# NPCX490M register map
File version: 1.0
Registers are 8-bit, read-write, reset 0x0 unless marked. A register's access mark holds for its fields unless they carry their own. Offsets are from the block's base; [hi:lo] are bit positions; {n}, {i} and the like mark numbered series; 'fields as' and 'values as' point back to an identical list.

## FIU_0
Base 0x40020000
Same registers: FIU_1 0x40021000
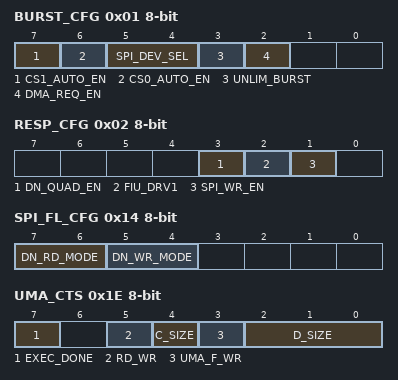
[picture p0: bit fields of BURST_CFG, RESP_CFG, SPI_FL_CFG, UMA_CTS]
0x01 BURST_CFG — Burst Configuration Register (BURST_CFG)
  [7] CS1_AUTO_EN — F_CS1 Auto-Assertion Enable
  [6] CS0_AUTO_EN — F_CS0 Auto-Assertion Enable
  [5:4] SPI_DEV_SEL — SPI Device Select
  [3] UNLIM_BURST — Unlimited Burst
  [2] DMA_REQ_EN — DMA Request Enable
0x02 RESP_CFG — FIU Response Configuration Register (RESP_CFG)
  [3] DN_QUAD_EN — Device 'n' Quad Enable
  [2] FIU_DRV1 — FIU IO2, IO3 Drive High
  [1] SPI_WR_EN — SPI Write Enable
0x14 SPI_FL_CFG — SPI Flash Configuration Register (SPI_FL_CFG)
  [7:6] DN_RD_MODE — Device 'n' Read Mode Select
  [5:4] DN_WR_MODE — Device 'n' Write Mode Select
0x16 UMA_CODE — UMA Code Byte Register (UMA_CODE)
{0x3+i} UMA_AB0-{i} (i=20..22) — UMA Address Byte 0-2 Register (UMA_AB0-2)
0x1A UMA_DB0-30 — UMA Data Byte 0-3 Register (UMA_DB0-3)
0x1B UMA_DB0-31 — UMA Data Byte 0-3 Register (UMA_DB0-3)
0x1C UMA_DB0-32 — UMA Data Byte 0-3 Register (UMA_DB0-3)
0x1D UMA_DB0-33 — UMA Data Byte 0-3 Register (UMA_DB0-3)
0x1E UMA_CTS — UMA Control and Status Register (UMA_CTS)
  [7] EXEC_DONE write-1-sets — Operation Execute/Done
  [5] RD_WR — Read/Write Select
  [4] C_SIZE — Code Field Size Select
  [3] UMA_F_WR — UMA Fast Write
  [2:0] D_SIZE — Data Field Size Select
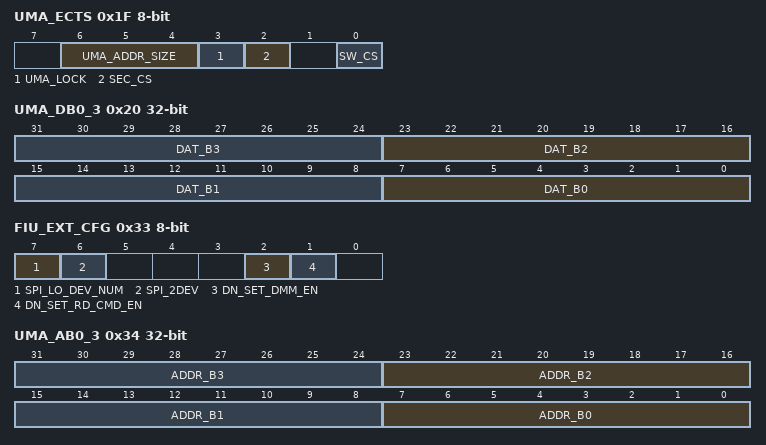
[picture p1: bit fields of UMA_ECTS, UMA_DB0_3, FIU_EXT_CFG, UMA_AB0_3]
0x1F UMA_ECTS — UMA Extended Control and Status Register (UMA_ECTS)
  [6:4] UMA_ADDR_SIZE — Address Field Size Select
  [3] UMA_LOCK write-1-sets — UMA Operation Lock
  [2] SEC_CS — Secondary Chip-Select
  [0] SW_CS — Software-Controlled Chip-Select
0x20 UMA_DB0_3 32-bit (reset mask 0xFF) — UMA Data Bytes 0-3 Register (UMA_DB0_3)
  [8n+7:8n] DAT_B{n} (n=0..3) — Data Byte {n}
0x25 UMA_DMM — UMA Dummy Register (UMA_DMM)
  [5:0] DMCSIZ — Dummy Cycles Size
0x30 Dn_FIU_RD_CMD — Device 'n' FIU Read Command Register (Dn_FIU_RD_CMD)
0x31 Dn_FIU_WR_CMD — Device 'n' FIU Write Command Register (Dn_FIU_WR_CMD)
0x32 Dn_FIU_DMM_CYC — Device 'n' FIU Dummy Cycle Register (Dn_FIU_DMM_CYC)
  [4:0] DN_DMM_CYC_NUM — Device 'n' Dummy Cycles Number
0x33 FIU_EXT_CFG — FIU Extended Configuration Register (FIU_EXT_CFG)
  [7] SPI_LO_DEV_NUM — SPI0 Low Device Number
  [6] SPI_2DEV — SPI Bus, Two Devices Enable
  [2] DN_SET_DMM_EN — Device 'n' Set Dummy Enable
  [1] DN_SET_RD_CMD_EN — Device 'n' Set Read Command Enable
0x34 UMA_AB0_3 32-bit (reset mask 0xFF) — UMA Address Byte 0_3 Register (UMA_AB0_3)
  [8n+7:8n] ADDR_B{n} (n=0..3) — Address Byte {n}
0x3C SPI_DEV — SPI Device Register (SPI_DEV)
  [7:5] DN_NADDRB — Device 'n' Number of Address Bytes
0x3E Dn_SPI_DEV_SIZE — Device 'n' SPI Device Size Register (Dn_SPI_DEV_SIZE)

## FLM
Base 0x400F8000
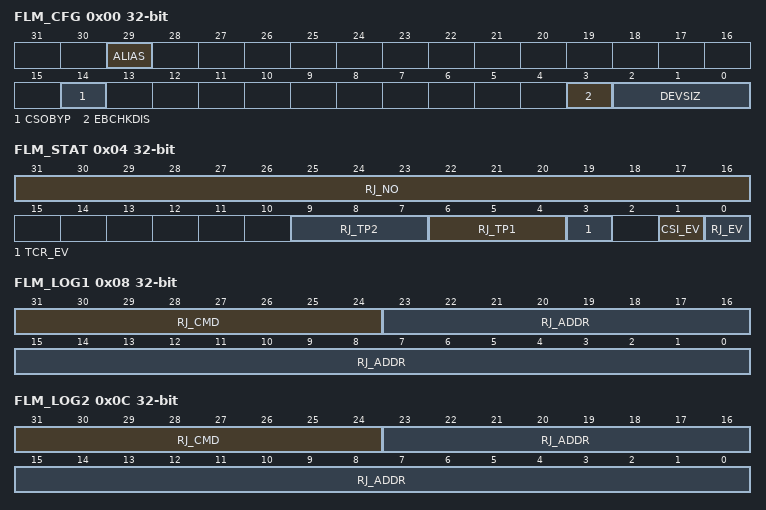
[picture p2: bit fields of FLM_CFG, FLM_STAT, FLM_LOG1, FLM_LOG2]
0x00 FLM_CFG 32-bit (reset mask 0xFF) — FLM Configuration Register (FLM_CFG)
  [29] ALIAS — Alias Flash Access Above Range
  [14] CSOBYP — FLM_CSIO Cut-Off Bypass
  [3] EBCHKDIS — Extra Bits Check Disable
  [2:0] DEVSIZ — Device Size
0x04 FLM_STAT 32-bit (reset mask 0xFF) — FLM Status Register (FLM_STAT)
  [31:16] RJ_NO ro — Rejection Number
  [9:7] RJ_TP2 ro — Rejection Type 2
  [6:4] RJ_TP1 ro — Rejection Type 1
  [3] TCR_EV write-1-clears — Transaction Counter Event
  [1] CSI_EV write-1-clears — Chip-Select Active Low Event
  [0] RJ_EV write-1-clears — Rejection Event
0x08 FLM_LOG1 32-bit ro (reset mask 0xFF) — FLM LOG Register 1
  [31:24] RJ_CMD — Rejection Command Byte
  [23:0] RJ_ADDR — Rejection Address
0x0C FLM_LOG2 32-bit ro (reset mask 0xFF) — FLM LOG Register 1-2 (FLM_LOG1-2)
  fields as FLM_LOG1
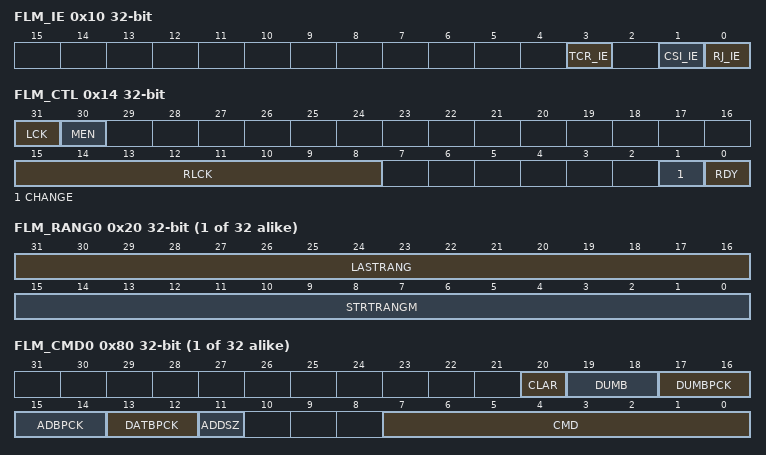
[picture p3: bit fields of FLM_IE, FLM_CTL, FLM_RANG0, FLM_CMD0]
0x10 FLM_IE 32-bit — FLM Interrupt Enable Register (FLM_IE)
  [3] TCR_IE — TCR_EV Interrupt Enable
  [1] CSI_IE — CSI_EV Interrupt Enable
  [0] RJ_IE — RJ_EV Interrupt Enable
0x14 FLM_CTL 32-bit (reset mask 0xFF) — FLM Control Register (FLM_CTL)
  [31] LCK write-1-sets — Lock
  [30] MEN — Module Enable
  [15:8] RLCK — Reversible Lock
  [1] CHANGE wo — Change and Update Configuration Parameters
  [0] RDY ro — Ready
{0x20+4i} FLM_RANG{i} (i=0..31) 32-bit (reset mask 0xFF) — FLM Range Register {i}
  [31:16] LASTRANG — Range Last Address
  [15:0] STRTRANGM — Range Start Address
0x60 FLM_CMDEN 32-bit (reset mask 0xFF) — FLM Command Enable (FLM_CMDEN)
0x64 FLM_CMBEN 32-bit (reset mask 0xFF) — FLM Command Byte Enable (FLM_CMBEN)
{0x80+4i} FLM_CMD{i} (i=0..31) 32-bit (reset mask 0xFF) — FLM Command Register {i}
  [20] CLAR — Command Limited Address Range
  [19:18] DUMB — Dummy Bytes
  [17:16] DUMBPCK — Dummy Bits Per Clock
  [15:14] ADBPCK — Address Bits Per Clock
  [13:12] DATBPCK — Data Bits Per Clock
  [11] ADDSZ — Address Size for Limiting Command
  [7:0] CMD — Command Byte
{0x100+4i} FLM_TCRA{i} (i=0..3) 32-bit ro (reset mask 0xFF) — FLM Transaction Counter Read Register A{i}
  [23:0] TCV — Transaction Counter Value
{0x110+4i} FLM_TCRB{i} (i=0..3) 32-bit ro (reset mask 0xFF) — FLM Transaction Counter Read Register B{i}
  [23:0] TCV — Transaction Counter Value
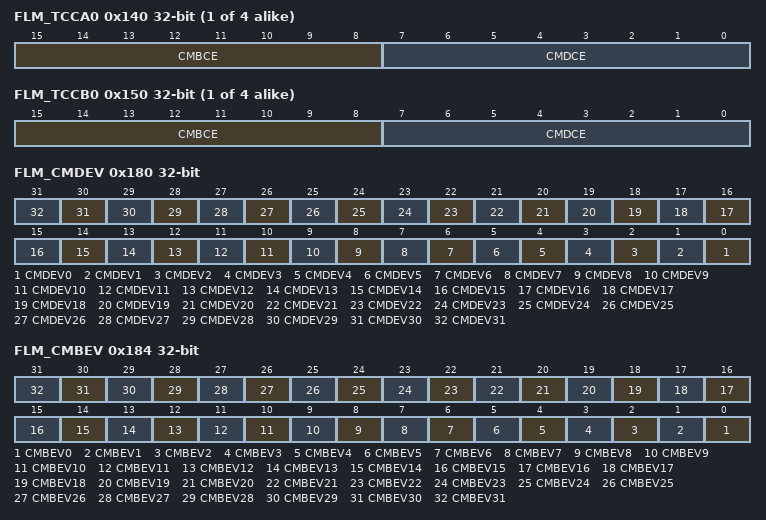
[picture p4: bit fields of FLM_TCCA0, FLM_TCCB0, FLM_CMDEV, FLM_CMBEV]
{0x140+4i} FLM_TCCA{i} (i=0..3) 32-bit (reset mask 0xFF) — FLM Transaction Counter Control Register A{i}
  [15:8] CMBCE — CMB Count Enable
  [7:0] CMDCE — CMD Count Enable
{0x150+4i} FLM_TCCB{i} (i=0..3) 32-bit (reset mask 0xFF) — FLM Transaction Counter Control Register B{i}
  [15:8] CMBCE — CMB Count Enable
  [7:0] CMDCE — CMD Count Enable
0x180 FLM_CMDEV 32-bit ro (reset mask 0xFF) — FLM CMD Event Register (FLM_CMDEV)
  [n] CMDEV{n} (n=0..31) — CMD Event {n}
0x184 FLM_CMBEV 32-bit ro (reset mask 0xFF) — FLM CMB Event Register (FLM_CMBEV)
  [n] CMBEV{n} (n=0..31) — CMB Event {n}
0x188 FLM_TCGC 32-bit wo — FLM Transaction Counter Global Control Register (FLM_TCGC)
  [0] TCCLR — Transaction Counters Clear
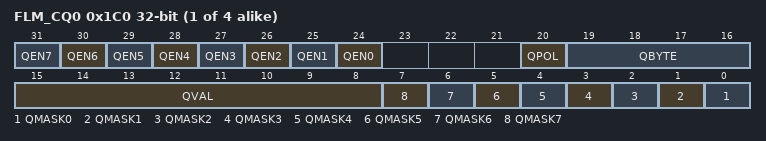
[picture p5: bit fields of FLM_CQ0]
{0x1C0+4i} FLM_CQ{i} (i=0..3) 32-bit (reset mask 0xFF) — FLM Command Qualifier Register {i}
  [n+24] QEN{n} (n=0..7) — Qualifier Enable
  [20] QPOL — Qualifier Compare Polarity
  [19:16] QBYTE — Qualifier Compare Byte Index
    1=FirstByte; 2=SecondByte; 3=ThirdByte; 4=FourthByte; 5=FifthByte; 6=SixthByte; 7=SeventhByte
  [15:8] QVAL — Qualifier Compare Value
  [n] QMASK{n} (n=0..7) — Qualifier Compare Mask
{0x200+4i} FLM_CMDARS{i} (i=0..31) 32-bit (reset mask 0xFF) — FLM Command Address Range Select Register {i}
  [15:0] CARSEL — Command Address Range Select
{0x280+4i} FLM_CMB{i} (i=0..31) 32-bit — FLM Command Byte Register {i}
  [7:0] CMD — Command Byte
